VERSION ""

NS_ :

BS_:
BU_: INTERCEPTOR NEO

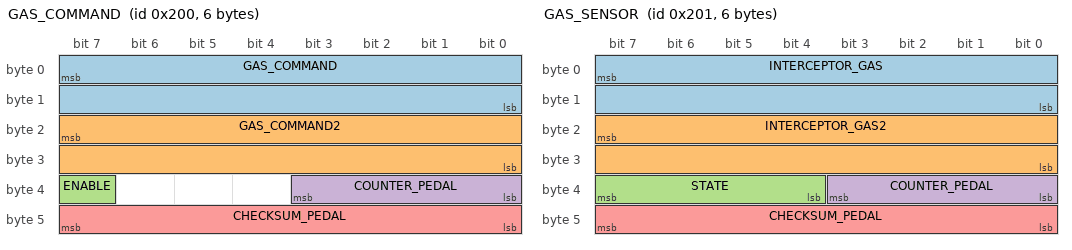
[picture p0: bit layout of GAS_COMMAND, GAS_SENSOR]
BO_ 512 GAS_COMMAND: 6 NEO
 SG_ GAS_COMMAND : 7|16@0+ (1,0) [0|65535] "" INTERCEPTOR
 SG_ GAS_COMMAND2 : 23|16@0+ (1,0) [0|65535] "" INTERCEPTOR
 SG_ ENABLE : 39|1@0+ (1,0) [0|1] "" INTERCEPTOR
 SG_ COUNTER_PEDAL : 35|4@0+ (1,0) [0|15] "" INTERCEPTOR
 SG_ CHECKSUM_PEDAL : 47|8@0+ (1,0) [0|255] "" INTERCEPTOR

BO_ 513 GAS_SENSOR: 6 INTERCEPTOR
 SG_ INTERCEPTOR_GAS : 7|16@0+ (1,0) [0|65535] "" NEO
 SG_ INTERCEPTOR_GAS2 : 23|16@0+ (1,0) [0|65535] "" NEO
 SG_ STATE : 39|4@0+ (1,0) [0|15] "" NEO
 SG_ COUNTER_PEDAL : 35|4@0+ (1,0) [0|15] "" NEO
 SG_ CHECKSUM_PEDAL : 47|8@0+ (1,0) [0|255] "" NEO

VAL_ 513 STATE 5 "FAULT_TIMEOUT" 4 "FAULT_STARTUP" 3 "FAULT_SCE" 2 "FAULT_SEND" 1 "FAULT_BAD_CHECKSUM" 0 "NO_FAULT" ;

CM_ "Comma Pedal raw wire protocol. Vehicle command conversion, driver thresholds and safety limits are configured separately. Do not merge these IDs into a vehicle DBC with different messages at 0x200/0x201.";
